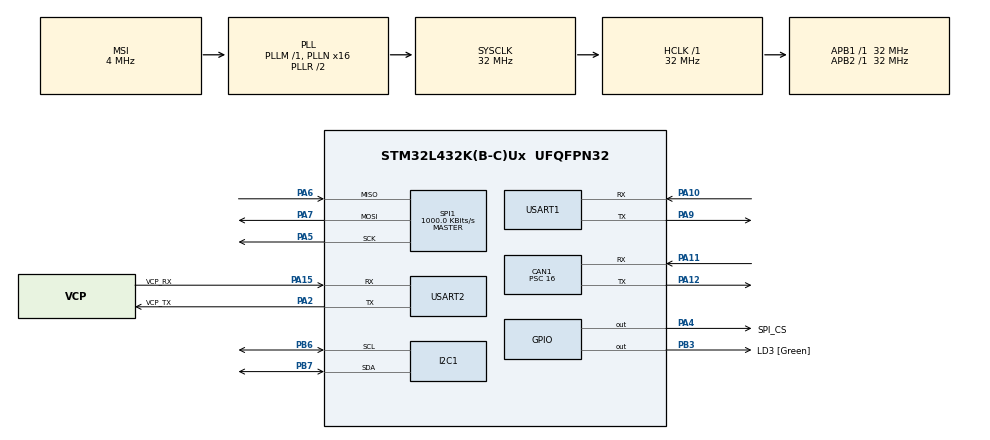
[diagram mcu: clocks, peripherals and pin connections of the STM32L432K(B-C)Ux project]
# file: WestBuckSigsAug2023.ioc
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CAN1.BS1=CAN_BS1_2TQ
CAN1.CalculateBaudRate=500000
CAN1.CalculateTimeBit=2000
CAN1.CalculateTimeQuantum=500.0
CAN1.Mode=CAN_MODE_LOOPBACK
CAN1.Prescaler=16
Dma.Request0=USART2_RX
Dma.Request1=USART1_RX
Dma.Request2=USART1_TX
Dma.Request3=USART2_TX
Dma.Request4=SPI1_RX
Dma.Request5=SPI1_TX
Dma.SPI1_RX.4.Direction=DMA_PERIPH_TO_MEMORY
Dma.SPI1_RX.4.Instance=DMA1_Channel2
Dma.SPI1_RX.4.MemDataAlignment=DMA_MDATAALIGN_BYTE
Dma.SPI1_RX.4.MemInc=DMA_MINC_ENABLE
Dma.SPI1_RX.4.Mode=DMA_NORMAL
Dma.SPI1_RX.4.PeriphDataAlignment=DMA_PDATAALIGN_BYTE
Dma.SPI1_RX.4.PeriphInc=DMA_PINC_DISABLE
Dma.SPI1_RX.4.Priority=DMA_PRIORITY_LOW
Dma.SPI1_TX.5.Direction=DMA_MEMORY_TO_PERIPH
Dma.SPI1_TX.5.Instance=DMA1_Channel3
Dma.SPI1_TX.5.MemDataAlignment=DMA_MDATAALIGN_BYTE
Dma.SPI1_TX.5.MemInc=DMA_MINC_ENABLE
Dma.SPI1_TX.5.Mode=DMA_NORMAL
Dma.SPI1_TX.5.PeriphDataAlignment=DMA_PDATAALIGN_BYTE
Dma.SPI1_TX.5.PeriphInc=DMA_PINC_DISABLE
Dma.SPI1_TX.5.Priority=DMA_PRIORITY_LOW
Dma.USART1_RX.1.Direction=DMA_PERIPH_TO_MEMORY
Dma.USART1_RX.1.Instance=DMA1_Channel5
Dma.USART1_RX.1.MemDataAlignment=DMA_MDATAALIGN_BYTE
Dma.USART1_RX.1.MemInc=DMA_MINC_ENABLE
Dma.USART1_RX.1.Mode=DMA_NORMAL
Dma.USART1_RX.1.PeriphDataAlignment=DMA_PDATAALIGN_BYTE
Dma.USART1_RX.1.PeriphInc=DMA_PINC_DISABLE
Dma.USART1_RX.1.Priority=DMA_PRIORITY_LOW
Dma.USART1_TX.2.Direction=DMA_MEMORY_TO_PERIPH
Dma.USART1_TX.2.Instance=DMA1_Channel4
Dma.USART1_TX.2.MemDataAlignment=DMA_MDATAALIGN_BYTE
Dma.USART1_TX.2.MemInc=DMA_MINC_ENABLE
Dma.USART1_TX.2.Mode=DMA_NORMAL
Dma.USART1_TX.2.PeriphDataAlignment=DMA_PDATAALIGN_BYTE
Dma.USART1_TX.2.PeriphInc=DMA_PINC_DISABLE
Dma.USART1_TX.2.Priority=DMA_PRIORITY_LOW
Dma.USART2_RX.0.Direction=DMA_PERIPH_TO_MEMORY
Dma.USART2_RX.0.Instance=DMA1_Channel6
Dma.USART2_RX.0.MemDataAlignment=DMA_MDATAALIGN_BYTE
Dma.USART2_RX.0.MemInc=DMA_MINC_ENABLE
Dma.USART2_RX.0.Mode=DMA_NORMAL
Dma.USART2_RX.0.PeriphDataAlignment=DMA_PDATAALIGN_BYTE
Dma.USART2_RX.0.PeriphInc=DMA_PINC_DISABLE
Dma.USART2_RX.0.Priority=DMA_PRIORITY_LOW
Dma.USART2_TX.3.Direction=DMA_MEMORY_TO_PERIPH
Dma.USART2_TX.3.Instance=DMA1_Channel7
Dma.USART2_TX.3.MemDataAlignment=DMA_MDATAALIGN_BYTE
Dma.USART2_TX.3.MemInc=DMA_MINC_ENABLE
Dma.USART2_TX.3.Mode=DMA_NORMAL
Dma.USART2_TX.3.PeriphDataAlignment=DMA_PDATAALIGN_BYTE
Dma.USART2_TX.3.PeriphInc=DMA_PINC_DISABLE
Dma.USART2_TX.3.Priority=DMA_PRIORITY_LOW
I2C1.Timing=0x00707CBB
Mcu.Family=STM32L4
Mcu.Name=STM32L432K(B-C)Ux
Mcu.Package=UFQFPN32
NVIC.CAN1_RX0_IRQn=true\:0\:0\:false\:false\:true\:true\:true\:true
NVIC.CAN1_RX1_IRQn=true\:0\:0\:false\:false\:true\:true\:true\:true
NVIC.CAN1_TX_IRQn=true\:0\:0\:false\:false\:true\:true\:true\:true
NVIC.DMA1_Channel2_IRQn=true\:0\:0\:false\:false\:true\:false\:true\:true
NVIC.DMA1_Channel3_IRQn=true\:0\:0\:false\:false\:true\:false\:true\:true
NVIC.DMA1_Channel4_IRQn=true\:0\:0\:false\:false\:true\:false\:true\:true
NVIC.DMA1_Channel5_IRQn=true\:0\:0\:false\:false\:true\:false\:true\:true
NVIC.DMA1_Channel6_IRQn=true\:0\:0\:false\:false\:true\:false\:true\:true
NVIC.DMA1_Channel7_IRQn=true\:0\:0\:false\:false\:true\:false\:true\:true
NVIC.PriorityGroup=NVIC_PRIORITYGROUP_4
NVIC.SPI1_IRQn=true\:0\:0\:false\:false\:true\:true\:true\:true
NVIC.TIM6_DAC_IRQn=true\:0\:0\:false\:false\:true\:true\:true\:true
NVIC.USART1_IRQn=true\:0\:0\:false\:false\:true\:true\:true\:true
NVIC.USART2_IRQn=true\:0\:0\:false\:false\:true\:true\:true\:true
PA0.GPIO_Label=MCO [High speed clock in]
PA0.Mode=HSE-External-Clock-Source-for-LittleOrca
PA0.Signal=RCC_CK_IN
PA10.Mode=Asynchronous
PA10.Signal=USART1_RX
PA11.Mode=CAN_Activate
PA11.Signal=CAN1_RX
PA12.Mode=CAN_Activate
PA12.Signal=CAN1_TX
PA13\ (JTMS-SWDIO).GPIO_Label=SWDIO
PA13\ (JTMS-SWDIO).Mode=Serial_Wire
PA13\ (JTMS-SWDIO).Signal=SYS_JTMS-SWDIO
PA14\ (JTCK-SWCLK).GPIO_Label=SWCLK
PA14\ (JTCK-SWCLK).Mode=Serial_Wire
PA14\ (JTCK-SWCLK).Signal=SYS_JTCK-SWCLK
PA15\ (JTDI).GPIO_Label=VCP_RX
PA15\ (JTDI).Mode=Asynchronous
PA15\ (JTDI).Signal=USART2_RX
PA2.GPIO_Label=VCP_TX
PA2.Mode=Asynchronous
PA2.Signal=USART2_TX
PA4.GPIO_Label=SPI_CS
PA4.PinState=GPIO_PIN_SET
PA4.Signal=GPIO_Output
PA5.Mode=Full_Duplex_Master
PA5.Signal=SPI1_SCK
PA6.Mode=Full_Duplex_Master
PA6.Signal=SPI1_MISO
PA7.Mode=Full_Duplex_Master
PA7.Signal=SPI1_MOSI
PA9.Mode=Asynchronous
PA9.Signal=USART1_TX
PB3\ (JTDO-TRACESWO).GPIO_Label=LD3 [Green]
PB3\ (JTDO-TRACESWO).Signal=GPIO_Output
PB6.Mode=I2C
PB6.Signal=I2C1_SCL
PB7.Mode=I2C
PB7.Signal=I2C1_SDA
PC14-OSC32_IN\ (PC14).Mode=LSE-External-Oscillator
PC14-OSC32_IN\ (PC14).Signal=RCC_OSC32_IN
PC15-OSC32_OUT\ (PC15).Mode=LSE-External-Oscillator
PC15-OSC32_OUT\ (PC15).Signal=RCC_OSC32_OUT
ProjectManager.HeapSize=0x200
ProjectManager.StackSize=0x400
ProjectManager.TargetToolchain=STM32CubeIDE
RCC.AHBFreq_Value=32000000
RCC.APB1Freq_Value=32000000
RCC.APB1TimFreq_Value=32000000
RCC.APB2Freq_Value=32000000
RCC.APB2TimFreq_Value=32000000
RCC.CortexFreq_Value=32000000
RCC.HCLKFreq_Value=32000000
RCC.HSE_VALUE=8000000
RCC.HSI16_VALUE=16000000
RCC.HSI48_VALUE=48000000
RCC.HSI_VALUE=16000000
RCC.MSI_VALUE=4000000
RCC.PLLMUL=RCC_PLLMUL_4
RCC.PLLN=16
RCC.SYSCLKFreq_VALUE=32000000
RCC.SYSCLKSource=RCC_SYSCLKSOURCE_PLLCLK
RCC.VCOOutputFreq_Value=64000000
SPI1.BaudRatePrescaler=SPI_BAUDRATEPRESCALER_32
SPI1.CalculateBaudRate=1000.0 KBits/s
SPI1.DataSize=SPI_DATASIZE_8BIT
SPI1.Direction=SPI_DIRECTION_2LINES
SPI1.Mode=SPI_MODE_MASTER
SPI1.NSSPMode=SPI_NSS_PULSE_DISABLE
SPI1.VirtualType=VM_MASTER
TIM6.AutoReloadPreload=TIM_AUTORELOAD_PRELOAD_ENABLE
TIM6.Period=1000 - 1
TIM6.Prescaler=32 - 1
TIM6.TIM_MasterOutputTrigger=TIM_TRGO_ENABLE
USART1.VirtualMode-Asynchronous=VM_ASYNC
USART2.DMADisableonRxErrorParam=ADVFEATURE_DMA_DISABLEONRXERROR
USART2.VirtualMode-Asynchronous=VM_ASYNC
VP_RTC_VS_RTC_Activate.Mode=RTC_Enabled
VP_RTC_VS_RTC_Calendar.Mode=RTC_Calendar
VP_TIM6_VS_ClockSourceINT.Mode=Enable_Timer
VP_TIM7_VS_ClockSourceINT.Mode=Enable_Timer
board=NUCLEO-L432KC

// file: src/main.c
/* USER CODE BEGIN Header */
/**
 *  Jon Freeman B Eng Hons
 *
 * WARNING
 * Code created using STM32CubeIDE from ST Microelectronics.
 * THIS FILE IS A MIX OF MACHINE-GENERATED / MAN-MADE CODE including most of the startup code
 *
 * YOU ARE STRONGLY ADVISED NOT TO EDIT THIS FILE
 *
  ******************************************************************************
  * @file           : main.c
  * @brief          : Main program body
  ******************************************************************************
  ******************************************************************************
  */
/* USER CODE END Header */
#include "main.h"

/* USER CODE BEGIN Includes */
#include	<stdio.h>
#include	<string.h>
#include	<stdbool.h>
/* USER CODE END Includes */

CAN_HandleTypeDef hcan1;

I2C_HandleTypeDef hi2c1;

RTC_HandleTypeDef hrtc;

SPI_HandleTypeDef hspi1;
DMA_HandleTypeDef hdma_spi1_rx;
DMA_HandleTypeDef hdma_spi1_tx;

TIM_HandleTypeDef htim6;
TIM_HandleTypeDef htim7;

UART_HandleTypeDef huart1;
UART_HandleTypeDef huart2;
DMA_HandleTypeDef hdma_usart1_rx;
DMA_HandleTypeDef hdma_usart1_tx;
DMA_HandleTypeDef hdma_usart2_rx;
DMA_HandleTypeDef hdma_usart2_tx;

/* USER CODE BEGIN PV */
uint32_t		input_test_error_flags = 0;

/* USER CODE END PV */

void SystemClock_Config(void);
static void MX_GPIO_Init(void);
static void MX_DMA_Init(void);
static void MX_USART2_UART_Init(void);
static void MX_USART1_UART_Init(void);
static void MX_TIM6_Init(void);
static void MX_SPI1_Init(void);
static void MX_CAN1_Init(void);
static void MX_I2C1_Init(void);
static void MX_TIM7_Init(void);
static void MX_RTC_Init(void);
/* USER CODE BEGIN PFP */

int16_t	onbuff	(UART_HandleTypeDef * huart)	;	//	Return number of characters waiting
extern	void	Signal_sys_Setup	()	;
extern	void	ForeverLoop	()	;
/* USER CODE END PFP */

/* USER CODE BEGIN 0 */

/*

CAN_TxHeaderTypeDef	TxHeader;
CAN_RxHeaderTypeDef	RxHeader;

uint8_t	MyCAN_TxData[8];
uint8_t	MyCAN_RxData[8];

uint32_t	cancount = 0;

void HAL_CAN_RxFifo0FullCallback(CAN_HandleTypeDef *hcan)	//	Not this one
{
	cancount++;
	HAL_CAN_GetRxMessage(&hcan1, CAN_RX_FIFO0, &RxHeader, MyCAN_RxData);
//	stdid[0] = RxHeader.StdId;
}

void HAL_CAN_RxFifo1FullCallback(CAN_HandleTypeDef *hcan)	//	Not this one
{
	cancount++;
	HAL_CAN_GetRxMessage(&hcan1, CAN_RX_FIFO1, &RxHeader, MyCAN_RxData);
//	stdid[1] = RxHeader.StdId;
}

void HAL_CAN_RxFifo0MsgPendingCallback(CAN_HandleTypeDef *hcan)	//	Yes this one
{
	cancount++;
	can_flag = true;
	HAL_CAN_GetRxMessage(&hcan1, CAN_RX_FIFO0, &RxHeader, MyCAN_RxData);
//	stdid[2] = RxHeader.StdId;
}

void HAL_CAN_RxFifo1MsgPendingCallback(CAN_HandleTypeDef *hcan)	//	Yes this one
{
	cancount++;
	HAL_CAN_GetRxMessage(&hcan1, CAN_RX_FIFO1, &RxHeader, MyCAN_RxData);
//	stdid[2] = RxHeader.StdId;
}
*/
/* USER CODE END 0 */

int main(void)
{

  /* MCU Configuration--------------------------------------------------------*/

  /* Reset of all peripherals, Initializes the Flash interface and the Systick. */
  HAL_Init();

  /* Configure the system clock */
  SystemClock_Config();

  /* Initialize all configured peripherals */
  MX_GPIO_Init();
  MX_DMA_Init();
  MX_USART2_UART_Init();
  MX_USART1_UART_Init();
  MX_TIM6_Init();
  MX_SPI1_Init();
  MX_CAN1_Init();
  MX_I2C1_Init();
  MX_TIM7_Init();
  MX_RTC_Init();
  /* USER CODE BEGIN 2 */
  // SPI CS pin should default high
//  spi_cs_set	();	//	No, this done by specifying initialise to '1' in .ioc setup

  HAL_TIM_Base_Start_IT(&htim6);	//	Need this to start timer
extern	void	start_uart_rx();

  start_uart_rx	();		//	Starts all used uarts
//  start_CAN_txrx	();	//	Now done as final step of init

/*  HAL_CAN_Start(&hcan1);

  if	(HAL_OK != HAL_CAN_ActivateNotification(&hcan1, CAN_IT_RX_FIFO0_MSG_PENDING))
	  cancount++;

  if	(HAL_OK != HAL_CAN_ActivateNotification(&hcan1, CAN_IT_RX_FIFO1_MSG_PENDING))
	  cancount++;*/
  /*
  TxHeader.DLC = 1;	//	Specifies length of data to send, bytes
  TxHeader.ExtId = 0;	//	Norm not extended
  TxHeader.IDE = CAN_ID_STD;
  TxHeader.RTR = CAN_RTR_DATA;
  TxHeader.StdId = 0x103;
  TxHeader.TransmitGlobalTime = DISABLE;

  TxData[0] = 0xf3;

  HAL_CAN_AddTxMessage(&hcan1, &TxHeader, TxData, &TxMailbox);
*/

  /* USER CODE END 2 */

  /* Infinite loop */
  /* USER CODE BEGIN WHILE */
  Signal_sys_Setup	();

  while (1)
  {
	  ForeverLoop	();			//	Into 'C++' code, Never returns
  }
    /* USER CODE END WHILE */

}

void SystemClock_Config(void)
{
  RCC_OscInitTypeDef RCC_OscInitStruct = {0};
  RCC_ClkInitTypeDef RCC_ClkInitStruct = {0};

  /** Configure the main internal regulator output voltage
  */
  if (HAL_PWREx_ControlVoltageScaling(PWR_REGULATOR_VOLTAGE_SCALE1) != HAL_OK)
  {
    Error_Handler();
  }

  /** Configure LSE Drive Capability
  */
  HAL_PWR_EnableBkUpAccess();
  __HAL_RCC_LSEDRIVE_CONFIG(RCC_LSEDRIVE_LOW);

  /** Initializes the RCC Oscillators according to the specified parameters
  * in the RCC_OscInitTypeDef structure.
  */
  RCC_OscInitStruct.OscillatorType = RCC_OSCILLATORTYPE_LSI|RCC_OSCILLATORTYPE_LSE
                              |RCC_OSCILLATORTYPE_MSI;
  RCC_OscInitStruct.LSEState = RCC_LSE_ON;
  RCC_OscInitStruct.LSIState = RCC_LSI_ON;
  RCC_OscInitStruct.MSIState = RCC_MSI_ON;
  RCC_OscInitStruct.MSICalibrationValue = 0;
  RCC_OscInitStruct.MSIClockRange = RCC_MSIRANGE_6;
  RCC_OscInitStruct.PLL.PLLState = RCC_PLL_ON;
  RCC_OscInitStruct.PLL.PLLSource = RCC_PLLSOURCE_MSI;
  RCC_OscInitStruct.PLL.PLLM = 1;
  RCC_OscInitStruct.PLL.PLLN = 16;
  RCC_OscInitStruct.PLL.PLLP = RCC_PLLP_DIV7;
  RCC_OscInitStruct.PLL.PLLQ = RCC_PLLQ_DIV2;
  RCC_OscInitStruct.PLL.PLLR = RCC_PLLR_DIV2;
  if (HAL_RCC_OscConfig(&RCC_OscInitStruct) != HAL_OK)
  {
    Error_Handler();
  }

  /** Initializes the CPU, AHB and APB buses clocks
  */
  RCC_ClkInitStruct.ClockType = RCC_CLOCKTYPE_HCLK|RCC_CLOCKTYPE_SYSCLK
                              |RCC_CLOCKTYPE_PCLK1|RCC_CLOCKTYPE_PCLK2;
  RCC_ClkInitStruct.SYSCLKSource = RCC_SYSCLKSOURCE_PLLCLK;
  RCC_ClkInitStruct.AHBCLKDivider = RCC_SYSCLK_DIV1;
  RCC_ClkInitStruct.APB1CLKDivider = RCC_HCLK_DIV1;
  RCC_ClkInitStruct.APB2CLKDivider = RCC_HCLK_DIV1;

  if (HAL_RCC_ClockConfig(&RCC_ClkInitStruct, FLASH_LATENCY_1) != HAL_OK)
  {
    Error_Handler();
  }

  /** Enable MSI Auto calibration
  */
  HAL_RCCEx_EnableMSIPLLMode();
}

static void MX_CAN1_Init(void)
{

  hcan1.Instance = CAN1;
  hcan1.Init.Prescaler = 16;
  hcan1.Init.Mode = CAN_MODE_LOOPBACK;
  hcan1.Init.SyncJumpWidth = CAN_SJW_1TQ;
  hcan1.Init.TimeSeg1 = CAN_BS1_2TQ;
  hcan1.Init.TimeSeg2 = CAN_BS2_1TQ;
  hcan1.Init.TimeTriggeredMode = DISABLE;
  hcan1.Init.AutoBusOff = DISABLE;
  hcan1.Init.AutoWakeUp = DISABLE;
  hcan1.Init.AutoRetransmission = DISABLE;
  hcan1.Init.ReceiveFifoLocked = DISABLE;
  hcan1.Init.TransmitFifoPriority = DISABLE;
  if (HAL_CAN_Init(&hcan1) != HAL_OK)
  {
    Error_Handler();
  }
  /* USER CODE BEGIN CAN1_Init 2 */
  extern	void  can_filter_setup();
  can_filter_setup();	//	Also starts CAN
////extern	void  can_filter_setup();
/*  CAN_FilterTypeDef	canfilterconfig;	//	Need to configure filters here
  canfilterconfig.FilterActivation = CAN_FILTER_ENABLE;
  canfilterconfig.FilterBank = 1;
  canfilterconfig.FilterFIFOAssignment = CAN_RX_FIFO0;
  canfilterconfig.FilterIdHigh = 0x0446 << 5;
  canfilterconfig.FilterIdLow = 0x0000;
  canfilterconfig.FilterMaskIdHigh = 0x0444 << 5;	//	'1' bit to compare filter bit to incoming bit
  canfilterconfig.FilterMaskIdLow = 0x0000;			//	'0' do not test bit in this position
  canfilterconfig.FilterMode = CAN_FILTERMODE_IDMASK;
  canfilterconfig.FilterScale = CAN_FILTERSCALE_32BIT;
//  canfilterconfig.SlaveStartFilterBank = 26;	//	Meaningless as only 1 CAN on L432KC
  HAL_CAN_ConfigFilter(&hcan1, &canfilterconfig);

  canfilterconfig.FilterBank = 6;
  canfilterconfig.FilterIdHigh = 0x0123 << 5;
  canfilterconfig.FilterMaskIdHigh = 0x0123 << 5;
  HAL_CAN_ConfigFilter(&hcan1, &canfilterconfig);

  canfilterconfig.FilterBank = 10;
  canfilterconfig.FilterIdHigh = 0x0700 << 5;
  canfilterconfig.FilterMaskIdHigh = 0x0700 << 5;
  HAL_CAN_ConfigFilter(&hcan1, &canfilterconfig);
*/
  /* USER CODE END CAN1_Init 2 */

}

static void MX_I2C1_Init(void)
{

  hi2c1.Instance = I2C1;
  hi2c1.Init.Timing = 0x00707CBB;
  hi2c1.Init.OwnAddress1 = 0;
  hi2c1.Init.AddressingMode = I2C_ADDRESSINGMODE_7BIT;
  hi2c1.Init.DualAddressMode = I2C_DUALADDRESS_DISABLE;
  hi2c1.Init.OwnAddress2 = 0;
  hi2c1.Init.OwnAddress2Masks = I2C_OA2_NOMASK;
  hi2c1.Init.GeneralCallMode = I2C_GENERALCALL_DISABLE;
  hi2c1.Init.NoStretchMode = I2C_NOSTRETCH_DISABLE;
  if (HAL_I2C_Init(&hi2c1) != HAL_OK)
  {
    Error_Handler();
  }

  /** Configure Analogue filter
  */
  if (HAL_I2CEx_ConfigAnalogFilter(&hi2c1, I2C_ANALOGFILTER_ENABLE) != HAL_OK)
  {
    Error_Handler();
  }

  /** Configure Digital filter
  */
  if (HAL_I2CEx_ConfigDigitalFilter(&hi2c1, 0) != HAL_OK)
  {
    Error_Handler();
  }

}

static void MX_RTC_Init(void)
{

  RTC_TimeTypeDef sTime = {0};
  RTC_DateTypeDef sDate = {0};

  /** Initialize RTC Only
  */
  hrtc.Instance = RTC;
  hrtc.Init.HourFormat = RTC_HOURFORMAT_24;
  hrtc.Init.AsynchPrediv = 127;
  hrtc.Init.SynchPrediv = 255;
  hrtc.Init.OutPut = RTC_OUTPUT_DISABLE;
  hrtc.Init.OutPutRemap = RTC_OUTPUT_REMAP_NONE;
  hrtc.Init.OutPutPolarity = RTC_OUTPUT_POLARITY_HIGH;
  hrtc.Init.OutPutType = RTC_OUTPUT_TYPE_OPENDRAIN;
  if (HAL_RTC_Init(&hrtc) != HAL_OK)
  {
    Error_Handler();
  }

  /** Initialize RTC and set the Time and Date
  */
  sTime.Hours = 0x0;
  sTime.Minutes = 0x0;
  sTime.Seconds = 0x0;
  sTime.DayLightSaving = RTC_DAYLIGHTSAVING_NONE;
  sTime.StoreOperation = RTC_STOREOPERATION_RESET;
  if (HAL_RTC_SetTime(&hrtc, &sTime, RTC_FORMAT_BCD) != HAL_OK)
  {
    Error_Handler();
  }
  sDate.WeekDay = RTC_WEEKDAY_MONDAY;
  sDate.Month = RTC_MONTH_JANUARY;
  sDate.Date = 0x1;
  sDate.Year = 0x0;

  if (HAL_RTC_SetDate(&hrtc, &sDate, RTC_FORMAT_BCD) != HAL_OK)
  {
    Error_Handler();
  }

}

static void MX_SPI1_Init(void)
{

  /* SPI1 parameter configuration*/
  hspi1.Instance = SPI1;
  hspi1.Init.Mode = SPI_MODE_MASTER;
  hspi1.Init.Direction = SPI_DIRECTION_2LINES;
  hspi1.Init.DataSize = SPI_DATASIZE_8BIT;
  hspi1.Init.CLKPolarity = SPI_POLARITY_LOW;
  hspi1.Init.CLKPhase = SPI_PHASE_1EDGE;
  hspi1.Init.NSS = SPI_NSS_SOFT;
  hspi1.Init.BaudRatePrescaler = SPI_BAUDRATEPRESCALER_32;
  hspi1.Init.FirstBit = SPI_FIRSTBIT_MSB;
  hspi1.Init.TIMode = SPI_TIMODE_DISABLE;
  hspi1.Init.CRCCalculation = SPI_CRCCALCULATION_DISABLE;
  hspi1.Init.CRCPolynomial = 7;
  hspi1.Init.CRCLength = SPI_CRC_LENGTH_DATASIZE;
  hspi1.Init.NSSPMode = SPI_NSS_PULSE_DISABLE;
  if (HAL_SPI_Init(&hspi1) != HAL_OK)
  {
    Error_Handler();
  }

}

static void MX_TIM6_Init(void)
{

  TIM_MasterConfigTypeDef sMasterConfig = {0};

  htim6.Instance = TIM6;
  htim6.Init.Prescaler = 32 - 1;
  htim6.Init.CounterMode = TIM_COUNTERMODE_UP;
  htim6.Init.Period = 1000 - 1;
  htim6.Init.AutoReloadPreload = TIM_AUTORELOAD_PRELOAD_ENABLE;
  if (HAL_TIM_Base_Init(&htim6) != HAL_OK)
  {
    Error_Handler();
  }
  sMasterConfig.MasterOutputTrigger = TIM_TRGO_ENABLE;
  sMasterConfig.MasterSlaveMode = TIM_MASTERSLAVEMODE_DISABLE;
  if (HAL_TIMEx_MasterConfigSynchronization(&htim6, &sMasterConfig) != HAL_OK)
  {
    Error_Handler();
  }

}

static void MX_TIM7_Init(void)
{

  TIM_MasterConfigTypeDef sMasterConfig = {0};

  htim7.Instance = TIM7;
  htim7.Init.Prescaler = 0;
  htim7.Init.CounterMode = TIM_COUNTERMODE_UP;
  htim7.Init.Period = 65535;
  htim7.Init.AutoReloadPreload = TIM_AUTORELOAD_PRELOAD_DISABLE;
  if (HAL_TIM_Base_Init(&htim7) != HAL_OK)
  {
    Error_Handler();
  }
  sMasterConfig.MasterOutputTrigger = TIM_TRGO_RESET;
  sMasterConfig.MasterSlaveMode = TIM_MASTERSLAVEMODE_DISABLE;
  if (HAL_TIMEx_MasterConfigSynchronization(&htim7, &sMasterConfig) != HAL_OK)
  {
    Error_Handler();
  }

}

static void MX_USART1_UART_Init(void)
{

  huart1.Instance = USART1;
  huart1.Init.BaudRate = 115200;
  huart1.Init.WordLength = UART_WORDLENGTH_8B;
  huart1.Init.StopBits = UART_STOPBITS_1;
  huart1.Init.Parity = UART_PARITY_NONE;
  huart1.Init.Mode = UART_MODE_TX_RX;
  huart1.Init.HwFlowCtl = UART_HWCONTROL_NONE;
  huart1.Init.OverSampling = UART_OVERSAMPLING_16;
  huart1.Init.OneBitSampling = UART_ONE_BIT_SAMPLE_DISABLE;
  huart1.AdvancedInit.AdvFeatureInit = UART_ADVFEATURE_NO_INIT;
  if (HAL_UART_Init(&huart1) != HAL_OK)
  {
    Error_Handler();
  }

}

static void MX_USART2_UART_Init(void)
{

  huart2.Instance = USART2;
  huart2.Init.BaudRate = 115200;
  huart2.Init.WordLength = UART_WORDLENGTH_8B;
  huart2.Init.StopBits = UART_STOPBITS_1;
  huart2.Init.Parity = UART_PARITY_NONE;
  huart2.Init.Mode = UART_MODE_TX_RX;
  huart2.Init.HwFlowCtl = UART_HWCONTROL_NONE;
  huart2.Init.OverSampling = UART_OVERSAMPLING_16;
  huart2.Init.OneBitSampling = UART_ONE_BIT_SAMPLE_DISABLE;
  huart2.AdvancedInit.AdvFeatureInit = UART_ADVFEATURE_DMADISABLEONERROR_INIT;
  huart2.AdvancedInit.DMADisableonRxError = UART_ADVFEATURE_DMA_DISABLEONRXERROR;
  if (HAL_UART_Init(&huart2) != HAL_OK)
  {
    Error_Handler();
  }

}

static void MX_DMA_Init(void)
{

  /* DMA controller clock enable */
  __HAL_RCC_DMA1_CLK_ENABLE();

  /* DMA interrupt init */
  /* DMA1_Channel2_IRQn interrupt configuration */
  HAL_NVIC_SetPriority(DMA1_Channel2_IRQn, 0, 0);
  HAL_NVIC_EnableIRQ(DMA1_Channel2_IRQn);
  /* DMA1_Channel3_IRQn interrupt configuration */
  HAL_NVIC_SetPriority(DMA1_Channel3_IRQn, 0, 0);
  HAL_NVIC_EnableIRQ(DMA1_Channel3_IRQn);
  /* DMA1_Channel4_IRQn interrupt configuration */
  HAL_NVIC_SetPriority(DMA1_Channel4_IRQn, 0, 0);
  HAL_NVIC_EnableIRQ(DMA1_Channel4_IRQn);
  /* DMA1_Channel5_IRQn interrupt configuration */
  HAL_NVIC_SetPriority(DMA1_Channel5_IRQn, 0, 0);
  HAL_NVIC_EnableIRQ(DMA1_Channel5_IRQn);
  /* DMA1_Channel6_IRQn interrupt configuration */
  HAL_NVIC_SetPriority(DMA1_Channel6_IRQn, 0, 0);
  HAL_NVIC_EnableIRQ(DMA1_Channel6_IRQn);
  /* DMA1_Channel7_IRQn interrupt configuration */
  HAL_NVIC_SetPriority(DMA1_Channel7_IRQn, 0, 0);
  HAL_NVIC_EnableIRQ(DMA1_Channel7_IRQn);

}

static void MX_GPIO_Init(void)
{
  GPIO_InitTypeDef GPIO_InitStruct = {0};

  /* GPIO Ports Clock Enable */
  __HAL_RCC_GPIOC_CLK_ENABLE();
  __HAL_RCC_GPIOA_CLK_ENABLE();
  __HAL_RCC_GPIOB_CLK_ENABLE();

  /*Configure GPIO pin Output Level */
  HAL_GPIO_WritePin(SPI_CS_GPIO_Port, SPI_CS_Pin, GPIO_PIN_SET);

  /*Configure GPIO pin Output Level */
  HAL_GPIO_WritePin(LD3_GPIO_Port, LD3_Pin, GPIO_PIN_RESET);

  /*Configure GPIO pin : SPI_CS_Pin */
  GPIO_InitStruct.Pin = SPI_CS_Pin;
  GPIO_InitStruct.Mode = GPIO_MODE_OUTPUT_PP;
  GPIO_InitStruct.Pull = GPIO_NOPULL;
  GPIO_InitStruct.Speed = GPIO_SPEED_FREQ_LOW;
  HAL_GPIO_Init(SPI_CS_GPIO_Port, &GPIO_InitStruct);

  /*Configure GPIO pin : LD3_Pin */
  GPIO_InitStruct.Pin = LD3_Pin;
  GPIO_InitStruct.Mode = GPIO_MODE_OUTPUT_PP;
  GPIO_InitStruct.Pull = GPIO_NOPULL;
  GPIO_InitStruct.Speed = GPIO_SPEED_FREQ_LOW;
  HAL_GPIO_Init(LD3_GPIO_Port, &GPIO_InitStruct);

}

void Error_Handler(void)
{
  __disable_irq();
  while (1)
  {
  }
}
